# ESP32-S31 register map
Vendor: ESPRESSIF SYSTEMS (SHANGHAI) CO., LTD.; Series: ESP32 S-Series; File version: 1
CPU: RV32IMAFC r0p0, little endian, no MPU, FPU, 0 interrupt priority bits
Address unit: 32 bits
Registers are 32-bit, read-write, reset 0x0 unless marked. A register's access mark holds for its fields unless they carry their own. Offsets are from the block's base; [hi:lo] are bit positions.

## LP_INTR — LP Interrupt Controller
Base 0x20714000
0x00 SW_INT_RAW
  [31] LP_SW_INT_RAW
0x04 SW_INT_ST ro
  [31] LP_SW_INT_ST
0x08 SW_INT_ENA
  [31] LP_SW_INT_ENA
0x0C SW_INT_CLR wo
  [31] LP_SW_INT_CLR
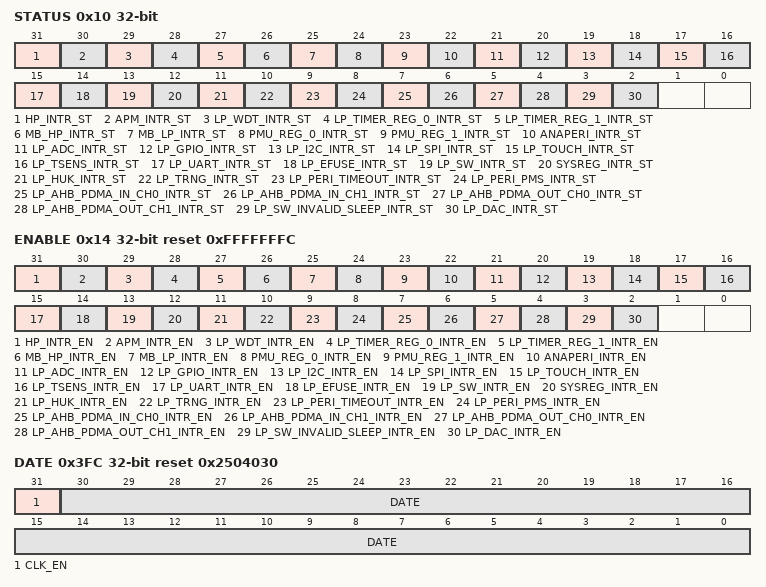
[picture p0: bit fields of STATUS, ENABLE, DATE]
0x10 STATUS ro
  [31] HP_INTR_ST, [30] APM_INTR_ST, [29] LP_WDT_INTR_ST, [28] LP_TIMER_REG_0_INTR_ST, [27] LP_TIMER_REG_1_INTR_ST, [26] MB_HP_INTR_ST, [25] MB_LP_INTR_ST, [24] PMU_REG_0_INTR_ST, [23] PMU_REG_1_INTR_ST, [22] ANAPERI_INTR_ST, [21] LP_ADC_INTR_ST, [20] LP_GPIO_INTR_ST, [19] LP_I2C_INTR_ST, [18] LP_SPI_INTR_ST, [17] LP_TOUCH_INTR_ST, [16] LP_TSENS_INTR_ST, [15] LP_UART_INTR_ST, [14] LP_EFUSE_INTR_ST, [13] LP_SW_INTR_ST, [12] SYSREG_INTR_ST, [11] LP_HUK_INTR_ST, [10] LP_TRNG_INTR_ST, [9] LP_PERI_TIMEOUT_INTR_ST, [8] LP_PERI_PMS_INTR_ST, [7] LP_AHB_PDMA_IN_CH0_INTR_ST, [6] LP_AHB_PDMA_IN_CH1_INTR_ST, [5] LP_AHB_PDMA_OUT_CH0_INTR_ST, [4] LP_AHB_PDMA_OUT_CH1_INTR_ST, [3] LP_SW_INVALID_SLEEP_INTR_ST, [2] LP_DAC_INTR_ST
0x14 ENABLE reset 0xFFFFFFFC
  [31] HP_INTR_EN, [30] APM_INTR_EN, [29] LP_WDT_INTR_EN, [28] LP_TIMER_REG_0_INTR_EN, [27] LP_TIMER_REG_1_INTR_EN, [26] MB_HP_INTR_EN, [25] MB_LP_INTR_EN, [24] PMU_REG_0_INTR_EN, [23] PMU_REG_1_INTR_EN, [22] ANAPERI_INTR_EN, [21] LP_ADC_INTR_EN, [20] LP_GPIO_INTR_EN, [19] LP_I2C_INTR_EN, [18] LP_SPI_INTR_EN, [17] LP_TOUCH_INTR_EN, [16] LP_TSENS_INTR_EN, [15] LP_UART_INTR_EN, [14] LP_EFUSE_INTR_EN, [13] LP_SW_INTR_EN, [12] SYSREG_INTR_EN, [11] LP_HUK_INTR_EN, [10] LP_TRNG_INTR_EN, [9] LP_PERI_TIMEOUT_INTR_EN, [8] LP_PERI_PMS_INTR_EN, [7] LP_AHB_PDMA_IN_CH0_INTR_EN, [6] LP_AHB_PDMA_IN_CH1_INTR_EN, [5] LP_AHB_PDMA_OUT_CH0_INTR_EN, [4] LP_AHB_PDMA_OUT_CH1_INTR_EN, [3] LP_SW_INVALID_SLEEP_INTR_EN, [2] LP_DAC_INTR_EN
0x3FC DATE reset 0x2504030
  [31] CLK_EN, [30:0] DATE

## LP_I2C_ANA_MST — LP_I2C_ANA_MST Peripheral
Base 0x20813000
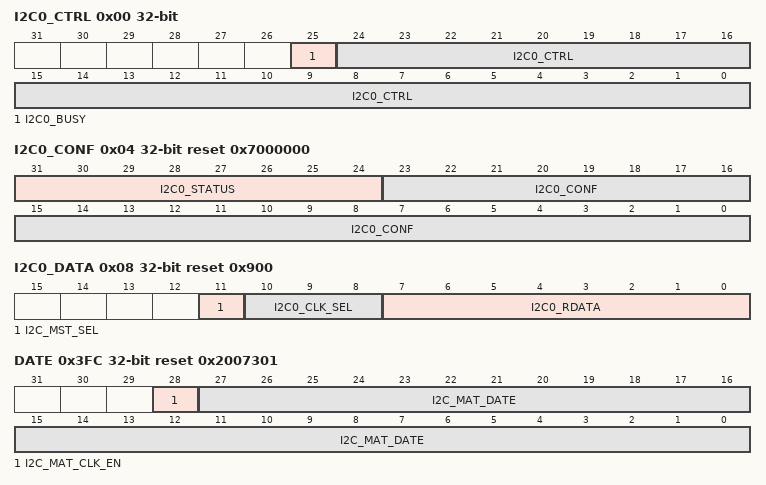
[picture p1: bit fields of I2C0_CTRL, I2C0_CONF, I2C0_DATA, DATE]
0x00 I2C0_CTRL access per field — need_des
  [25] I2C0_BUSY ro — need_des
  [24:0] I2C0_CTRL rw — need_des
0x04 I2C0_CONF access per field reset 0x7000000 — need_des
  [31:24] I2C0_STATUS ro — reserved
  [23:0] I2C0_CONF rw — need_des
0x08 I2C0_DATA access per field reset 0x900 — need_des
  [11] I2C_MST_SEL rw — need des
  [10:8] I2C0_CLK_SEL rw — need_des
  [7:0] I2C0_RDATA ro — need_des
0x0C ANA_CONF1 — need_des
  [23:0] ANA_CONF1
0x10 NOUSE — need_des
  [31:0] I2C_MST_NOUSE
0x14 DEVICE_EN — need_des
  [11:0] I2C_DEVICE_EN
0x3FC DATE reset 0x2007301 — need_des
  [28] I2C_MAT_CLK_EN — need_des
  [27:0] I2C_MAT_DATE — need_des

## LP_PERICLKRST — LP_PERICLKRST Peripheral
Base 0x20710000
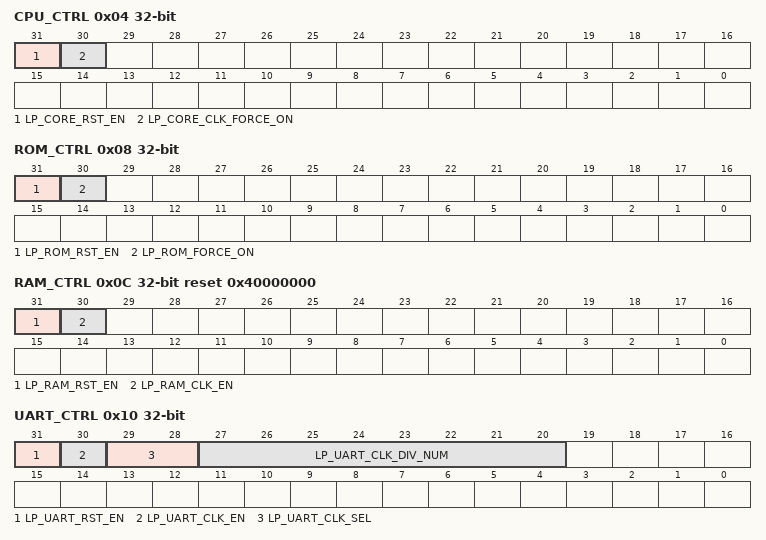
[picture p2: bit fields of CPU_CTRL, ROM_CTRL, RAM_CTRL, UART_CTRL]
0x04 CPU_CTRL access per field — need_des
  [31] LP_CORE_RST_EN wo — need_des
  [30] LP_CORE_CLK_FORCE_ON rw — need_des
0x08 ROM_CTRL — need_des
  [31] LP_ROM_RST_EN — need_des
  [30] LP_ROM_FORCE_ON — need_des
0x0C RAM_CTRL reset 0x40000000 — need_des
  [31] LP_RAM_RST_EN — need_des
  [30] LP_RAM_CLK_EN — need_des
0x10 UART_CTRL — need_des
  [31] LP_UART_RST_EN — need_des
  [30] LP_UART_CLK_EN — need_des
  [29:28] LP_UART_CLK_SEL — need_des
  [27:20] LP_UART_CLK_DIV_NUM — need_des
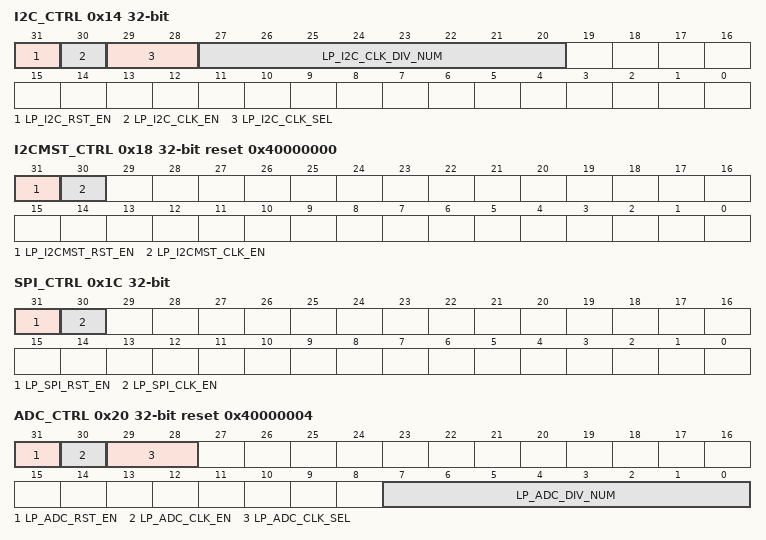
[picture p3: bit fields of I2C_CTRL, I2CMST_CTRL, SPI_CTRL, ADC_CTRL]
0x14 I2C_CTRL — need_des
  [31] LP_I2C_RST_EN — need_des
  [30] LP_I2C_CLK_EN — need_des
  [29:28] LP_I2C_CLK_SEL — need_des
  [27:20] LP_I2C_CLK_DIV_NUM — need_des
0x18 I2CMST_CTRL reset 0x40000000 — need_des
  [31] LP_I2CMST_RST_EN — need_des
  [30] LP_I2CMST_CLK_EN — need_des
0x1C SPI_CTRL — need_des
  [31] LP_SPI_RST_EN — need_des
  [30] LP_SPI_CLK_EN — need_des
0x20 ADC_CTRL reset 0x40000004 — need_des
  [31] LP_ADC_RST_EN — need_des
  [30] LP_ADC_CLK_EN — need_des
  [29:28] LP_ADC_CLK_SEL — need_des
  [7:0] LP_ADC_DIV_NUM — need_des
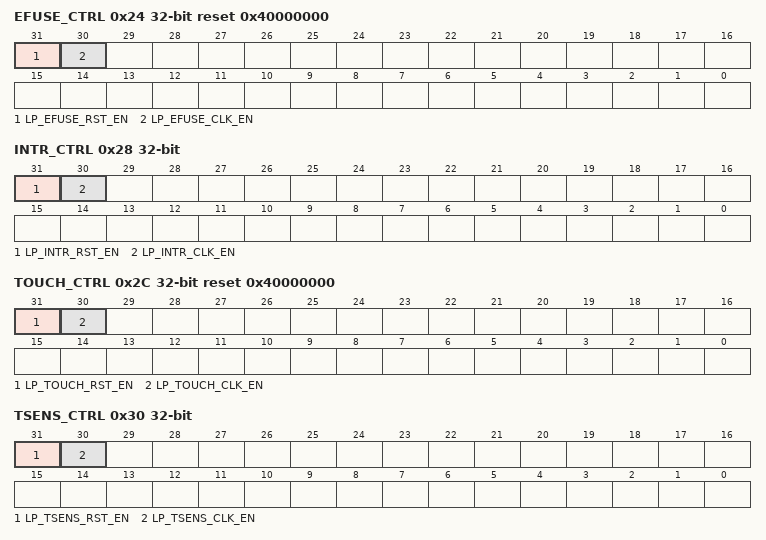
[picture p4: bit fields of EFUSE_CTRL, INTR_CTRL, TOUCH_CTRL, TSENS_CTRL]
0x24 EFUSE_CTRL reset 0x40000000 — need_des
  [31] LP_EFUSE_RST_EN — need_des
  [30] LP_EFUSE_CLK_EN — need_des
0x28 INTR_CTRL — need_des
  [31] LP_INTR_RST_EN — need_des
  [30] LP_INTR_CLK_EN — need_des
0x2C TOUCH_CTRL reset 0x40000000 — need_des
  [31] LP_TOUCH_RST_EN — need_des
  [30] LP_TOUCH_CLK_EN — need_des
0x30 TSENS_CTRL — need_des
  [31] LP_TSENS_RST_EN — need_des
  [30] LP_TSENS_CLK_EN — need_des
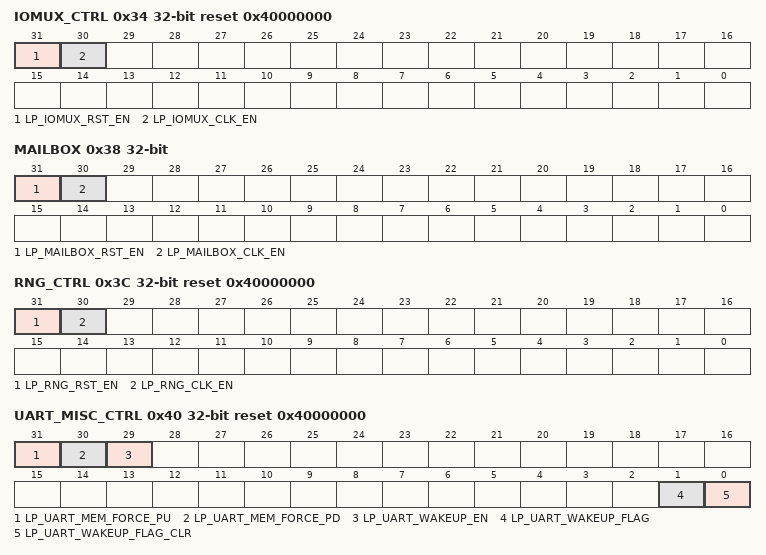
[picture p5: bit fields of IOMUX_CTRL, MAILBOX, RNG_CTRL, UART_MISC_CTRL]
0x34 IOMUX_CTRL reset 0x40000000 — need_des
  [31] LP_IOMUX_RST_EN — need_des
  [30] LP_IOMUX_CLK_EN — need_des
0x38 MAILBOX — need_des
  [31] LP_MAILBOX_RST_EN — need_des
  [30] LP_MAILBOX_CLK_EN — need_des
0x3C RNG_CTRL reset 0x40000000 — need_des
  [31] LP_RNG_RST_EN — need_des
  [30] LP_RNG_CLK_EN — need_des
0x40 UART_MISC_CTRL access per field reset 0x40000000 — need_des
  [31] LP_UART_MEM_FORCE_PU rw — need_des
  [30] LP_UART_MEM_FORCE_PD rw — need_des
  [29] LP_UART_WAKEUP_EN rw — need_des
  [1] LP_UART_WAKEUP_FLAG rw — need_des
  [0] LP_UART_WAKEUP_FLAG_CLR wo — need_des
0x44 CPU reset 0x80000000 — need_des
  [31] LPCORE_DBGM_UNAVAILABLE
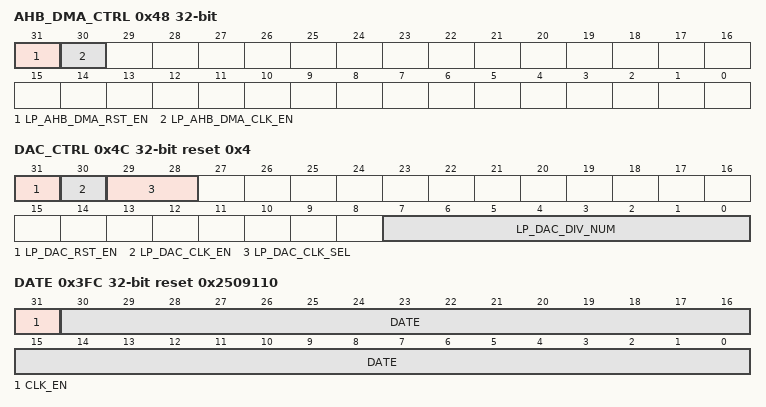
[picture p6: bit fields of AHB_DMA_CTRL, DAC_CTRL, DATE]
0x48 AHB_DMA_CTRL — need_des
  [31] LP_AHB_DMA_RST_EN — need_des
  [30] LP_AHB_DMA_CLK_EN — need_des
0x4C DAC_CTRL reset 0x4 — need_des
  [31] LP_DAC_RST_EN — need_des
  [30] LP_DAC_CLK_EN — need_des
  [29:28] LP_DAC_CLK_SEL — need_des
  [7:0] LP_DAC_DIV_NUM — need_des
0x50 DM_CTRL reset 0x80000000 — need_des
  [31] LP_DM_CLK_EN
0x3FC DATE reset 0x2509110 — need_des
  [31] CLK_EN — need_des
  [30:0] DATE — need_des
